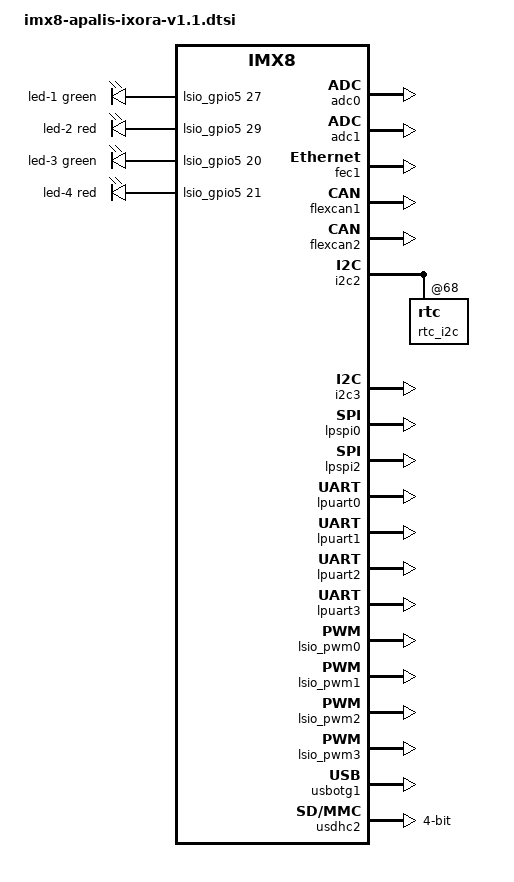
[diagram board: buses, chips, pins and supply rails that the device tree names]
#include <dt-bindings/leds/common.h>
/ {
	aliases {
		rtc0 = &rtc_i2c;
		rtc1 = &rtc;
	};
	leds {
		compatible = "gpio-leds";
		pinctrl-names = "default";
		pinctrl-0 = <&pinctrl_leds_ixora>;
		led-1 {
			color = <LED_COLOR_ID_GREEN>;
			default-state = "off";
			function = LED_FUNCTION_STATUS;
			gpios = <&lsio_gpio5 27 GPIO_ACTIVE_HIGH>;
		};
		led-2 {
			color = <LED_COLOR_ID_RED>;
			default-state = "off";
			function = LED_FUNCTION_STATUS;
			gpios = <&lsio_gpio5 29 GPIO_ACTIVE_HIGH>;
		};
		led-3 {
			color = <LED_COLOR_ID_GREEN>;
			default-state = "off";
			function = LED_FUNCTION_STATUS;
			gpios = <&lsio_gpio5 20 GPIO_ACTIVE_HIGH>;
		};
		led-4 {
			color = <LED_COLOR_ID_RED>;
			default-state = "off";
			function = LED_FUNCTION_STATUS;
			gpios = <&lsio_gpio5 21 GPIO_ACTIVE_HIGH>;
		};
	};
	reg_usb_host_vbus: regulator-usb-host-vbus {
		regulator-name = "VCC_USBH(2|4)";
	};
};
&adc0 {
	status = "okay";
};
&adc1 {
	status = "okay";
};
&fec1 {
	status = "okay";
};
&flexcan1 {
	status = "okay";
};
&flexcan2 {
	status = "okay";
};
&i2c2 {
	status = "okay";
	rtc_i2c: rtc@68 {
		status = "okay";
	};
};
&i2c3 {
	status = "okay";
};
&iomuxc {
	pinctrl-0 = <&pinctrl_cam1_gpios>, <&pinctrl_dap1_gpios>,
		    <&pinctrl_esai0_gpios>, <&pinctrl_fec2_gpios>,
		    <&pinctrl_gpio3>, <&pinctrl_gpio4>, <&pinctrl_gpio_usbh_oc_n>,
		    <&pinctrl_lpuart1ctrl>, <&pinctrl_lvds0_i2c0_gpio>,
		    <&pinctrl_lvds1_i2c0_gpios>, <&pinctrl_mipi_dsi_0_1_en>,
		    <&pinctrl_mipi_dsi1_gpios>, <&pinctrl_mlb_gpios>,
		    <&pinctrl_qspi1a_gpios>, <&pinctrl_sata1_act>,
		    <&pinctrl_sim0_gpios>, <&pinctrl_uart24_forceoff>,
		    <&pinctrl_usdhc1_gpios>;
	pinctrl_leds_ixora: ledsixoragrp {
		fsl,pins = <IMX8QM_USDHC2_DATA1_LSIO_GPIO5_IO27	0x06000061>,  
			   <IMX8QM_USDHC2_DATA3_LSIO_GPIO5_IO29	0x06000061>,  
			   <IMX8QM_USDHC1_DATA5_LSIO_GPIO5_IO20	0x06000061>,  
			   <IMX8QM_USDHC1_DATA6_LSIO_GPIO5_IO21	0x06000061>;  
	};
	pinctrl_uart24_forceoff: uart24forceoffgrp {
		fsl,pins = <IMX8QM_USDHC2_CMD_LSIO_GPIO5_IO25		0x00000021>;
	};
};
&lpspi0 {
	status = "okay";
};
&lpspi2 {
	status = "okay";
};
&lpuart0 {
	status = "okay";
};
&lpuart1 {
	status = "okay";
};
&lpuart2 {
	status = "okay";
};
&lpuart3 {
	status = "okay";
};
&lsio_gpio5 {
	gpio-line-names = "gpio5-00", "gpio5-01", "gpio5-02", "gpio5-03",
			  "gpio5-04", "gpio5-05", "gpio5-06", "gpio5-07",
			  "gpio5-08", "gpio5-09", "gpio5-10", "gpio5-11",
			  "gpio5-12", "gpio5-13", "gpio5-14", "gpio5-15",
			  "gpio5-16", "gpio5-17", "gpio5-18", "gpio5-19",
			  "LED-5-GREEN", "LED-5-RED", "gpio5-22", "gpio5-23",
			  "gpio5-24", "UART24-FORCEOFF", "gpio5-26",
			  "LED-4-GREEN", "gpio5-28", "LED-4-RED", "gpio5-30",
			  "gpio5-31";
	ngpios = <32>;
};
&lsio_pwm0 {
	status = "okay";
};
&lsio_pwm1 {
	status = "okay";
};
&lsio_pwm2 {
	status = "okay";
};
&lsio_pwm3 {
	status = "okay";
};
&usbotg1 {
	status = "okay";
};
&usdhc2 {
	pinctrl-0 = <&pinctrl_usdhc2_4bit>, <&pinctrl_mmc1_cd>;
	pinctrl-1 = <&pinctrl_usdhc2_4bit_100mhz>, <&pinctrl_mmc1_cd>;
	pinctrl-2 = <&pinctrl_usdhc2_4bit_200mhz>, <&pinctrl_mmc1_cd>;
	pinctrl-3 = <&pinctrl_usdhc2_4bit_sleep>, <&pinctrl_mmc1_cd_sleep>;
	bus-width = <4>;
	status = "okay";
};
